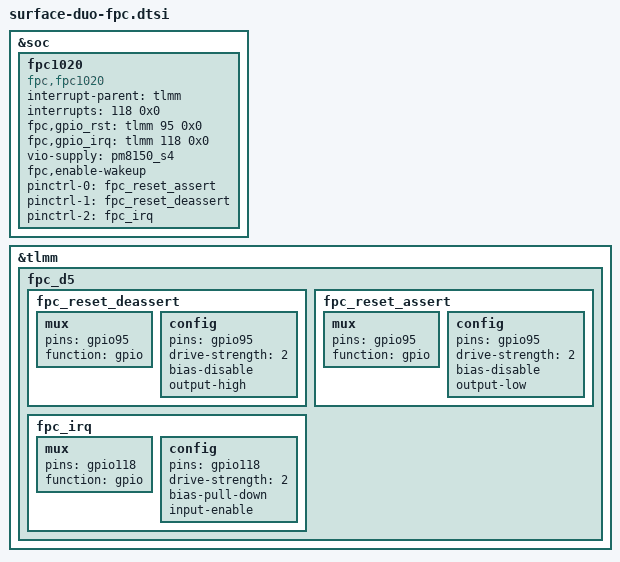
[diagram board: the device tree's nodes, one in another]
/*
 * Copyright (c) 2020 Microsoft Corporation
 *
 * This program is free software; you can redistribute it and/or modify it
 * under the terms of the GNU General Public License version 2 as published by
 * the Free Software Foundation.
 */
&soc {
        fpc1020 {
                status = "ok";
                compatible = "fpc,fpc1020";
                interrupt-parent = <&tlmm>;
                interrupts = <118 0x0>;
                fpc,gpio_rst = <&tlmm 95 0x0>;
                fpc,gpio_irq = <&tlmm 118 0x0>;
                vio-supply = <&pm8150_s4>;
                fpc,enable-wakeup;

                pinctrl-names = "fpc1020_reset_reset",
                        "fpc1020_reset_active",
                        "fpc1020_irq_active";

                pinctrl-0 = <&fpc_reset_assert>;
                pinctrl-1 = <&fpc_reset_deassert>;
                pinctrl-2 = <&fpc_irq>;
        };
};

&tlmm {
	fpc_d5 {
		fpc_reset_deassert: fpc_reset_deassert {
			mux {
				pins = "gpio95";
				function = "gpio";
			};

			config {
				pins = "gpio95";
				drive-strength = <2>;
				bias-disable;
				output-high;
			};
		};

		fpc_reset_assert: fpc_reset_assert {
			mux {
				pins = "gpio95";
				function = "gpio";
			};

			config {
				pins = "gpio95" ;
				drive-strength = <2>;
				bias-disable;
				output-low;
			};
		};
		fpc_irq: fpc_irq {
			mux {
				pins = "gpio118";
				function = "gpio";
			};

			config {
				pins = "gpio118" ;
				drive-strength = <2>;
				bias-pull-down;
				input-enable;
			};
		};
	};
};
